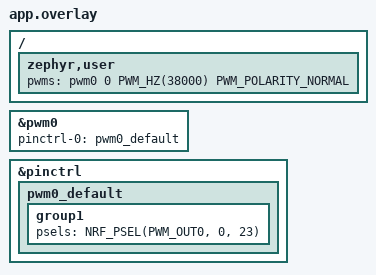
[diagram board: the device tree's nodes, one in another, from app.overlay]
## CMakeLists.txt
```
cmake_minimum_required(VERSION 3.20.0)
set(BOARD_ROOT ${CMAKE_CURRENT_SOURCE_DIR}/../.. CACHE PATH "")
find_package(Zephyr REQUIRED HINTS $ENV{ZEPHYR_BASE})
project(irtester)

target_sources(app PRIVATE
    src/main_rx_debug.c
    src/ir.c
)
```

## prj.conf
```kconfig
CONFIG_LOG=y
CONFIG_GPIO=y
CONFIG_PWM=y
```

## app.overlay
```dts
/ {
    zephyr,user {
        pwms = <&pwm0 0 PWM_HZ(38000) PWM_POLARITY_NORMAL>;
    };
};

&pwm0 {
    status = "okay";
    pinctrl-0 = <&pwm0_default>;
    pinctrl-names = "default";
};

&pinctrl {
    pwm0_default: pwm0_default {
        group1 {
            psels = <NRF_PSEL(PWM_OUT0, 0, 23)>;
        };
    };
};
```

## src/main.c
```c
#include <stdint.h>
#include <string.h>

#include <zephyr/kernel.h>
#include <zephyr/logging/log.h>
#include <zephyr/logging/log_core.h>

#include "ir.h"

LOG_MODULE_REGISTER(irtester, LOG_LEVEL_INF);

#define IR_MESSAGE "TH-1"
#define IR_MESSAGE_LEN (sizeof(IR_MESSAGE) - 1)

int main(void)
{
	int err;
	uint8_t decoded[IR_MESSAGE_LEN] = {0};
	int bytes_decoded;
	int edges_captured;

	LOG_INF("irtester starting");

	err = ir_tx_init();
	if (err) {
		return err;
	}

	err = ir_rx_init();
	if (err) {
		return err;
	}

	LOG_INF("Sending message \"%s\" over IR", IR_MESSAGE);

	ir_rx_capture_start();
	for (size_t i = 0; i < IR_MESSAGE_LEN; i++) {
		ir_send_byte((uint8_t)IR_MESSAGE[i]);
	}
	k_msleep(5);
	edges_captured = ir_rx_capture_stop();

	if (edges_captured == 0) {
		LOG_WRN("No response seen on the IR receiver at all");
		return 0;
	}

	LOG_INF("Response detected on IR receiver (%d edge(s))", edges_captured);

	bytes_decoded = ir_decode_capture(decoded, (int)IR_MESSAGE_LEN);
	if (bytes_decoded == (int)IR_MESSAGE_LEN &&
	    memcmp(decoded, IR_MESSAGE, IR_MESSAGE_LEN) == 0) {
		LOG_INF("Decoded message matches what was sent: \"%.*s\"",
			(int)IR_MESSAGE_LEN, decoded);
	} else {
		LOG_WRN("Only decoded %d of %zu byte(s):", bytes_decoded, IR_MESSAGE_LEN);
		for (int i = 0; i < bytes_decoded; i++) {
			char c = (decoded[i] >= 32 && decoded[i] < 127) ? (char)decoded[i] : '?';

			LOG_WRN("  byte %d: 0x%02x ('%c')", i, decoded[i], c);
		}
	}

	return 0;
}
```

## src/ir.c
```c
#include <errno.h>

#include <zephyr/kernel.h>
#include <zephyr/device.h>
#include <zephyr/devicetree.h>
#include <zephyr/drivers/gpio.h>
#include <zephyr/drivers/pwm.h>
#include <zephyr/sys/util.h>
#include <zephyr/sys/time_units.h>
#include <zephyr/logging/log.h>
#include <zephyr/logging/log_core.h>

#include "ir.h"

LOG_MODULE_REGISTER(ir, LOG_LEVEL_INF);

static const struct pwm_dt_spec pwm_ir = PWM_DT_SPEC_GET(DT_PATH(zephyr_user));
static const struct gpio_dt_spec ir_rx = GPIO_DT_SPEC_GET(DT_PATH(zephyr_user), ir_rx_gpios);

static struct gpio_callback ir_rx_cb_data;
static struct ir_edge capture_buf[IR_CAPTURE_MAX];
static volatile int capture_count;

static inline void ir_carrier_on(void)
{
	pwm_set_dt(&pwm_ir, pwm_ir.period, pwm_ir.period / 2);
}

static inline void ir_carrier_off(void)
{
	pwm_set_dt(&pwm_ir, pwm_ir.period, 0);
}

static void ir_mark(uint32_t us)
{
	ir_carrier_on();
	k_busy_wait(us);
	ir_carrier_off();
}

static void ir_space(uint32_t us)
{
	k_busy_wait(us);
}

static void ir_rx_isr(const struct device *port, struct gpio_callback *cb,
		       gpio_port_pins_t pins)
{
	ARG_UNUSED(port);
	ARG_UNUSED(cb);
	ARG_UNUSED(pins);

	if (capture_count >= IR_CAPTURE_MAX) {
		return;
	}

	capture_buf[capture_count].timestamp_cycles = k_cycle_get_32();
	capture_buf[capture_count].active = gpio_pin_get_dt(&ir_rx) == 1;
	capture_count++;
}

int ir_tx_init(void)
{
	if (!pwm_is_ready_dt(&pwm_ir)) {
		LOG_ERR("PWM device for IR TX is not ready");
		return -ENODEV;
	}

	return pwm_set_dt(&pwm_ir, pwm_ir.period, 0);
}

int ir_rx_init(void)
{
	int err;

	if (!gpio_is_ready_dt(&ir_rx)) {
		LOG_ERR("GPIO device for IR RX is not ready");
		return -ENODEV;
	}

	err = gpio_pin_configure_dt(&ir_rx, GPIO_INPUT);
	if (err) {
		LOG_ERR("Failed to configure IR RX pin as input (err: %d)", err);
		return err;
	}

	gpio_init_callback(&ir_rx_cb_data, ir_rx_isr, BIT(ir_rx.pin));

	err = gpio_add_callback_dt(&ir_rx, &ir_rx_cb_data);
	if (err) {
		LOG_ERR("Failed to add IR RX gpio callback (err: %d)", err);
		return err;
	}

	return 0;
}

void ir_send_byte(uint8_t byte)
{
	ir_mark(IR_HEADER_MARK_US);
	ir_space(IR_HEADER_SPACE_US);

	for (int i = 0; i < 8; i++) {
		ir_mark(IR_BIT_MARK_US);
		if (byte & BIT(i)) {
			ir_space(IR_ONE_SPACE_US);
		} else {
			ir_space(IR_ZERO_SPACE_US);
		}
	}

	ir_mark(IR_BIT_MARK_US);
	ir_carrier_off();
}

void ir_rx_capture_start(void)
{
	capture_count = 0;
	gpio_pin_interrupt_configure_dt(&ir_rx, GPIO_INT_EDGE_BOTH);
}

int ir_rx_capture_stop(void)
{
	gpio_pin_interrupt_configure_dt(&ir_rx, GPIO_INT_DISABLE);
	return capture_count;
}

static uint32_t edge_delta_us(int idx)
{
	uint32_t delta_cycles = capture_buf[idx + 1].timestamp_cycles -
				 capture_buf[idx].timestamp_cycles;

	return k_cyc_to_us_floor32(delta_cycles);
}

/* Finds a header mark at or after idx and returns the index of the start of
 * bit 0's mark (i.e. just past the header space), or -1 if no complete
 * header is found. Generous tolerance on the header mark's duration since
 * the two halves of this board are not aimed at each other and some
 * corruption is expected. */
static int find_header(int idx, int n)
{
	while (idx < n - 1) {
		if (capture_buf[idx].active &&
		    edge_delta_us(idx) > IR_HEADER_MARK_US / 2 &&
		    edge_delta_us(idx) < IR_HEADER_MARK_US * 2) {
			break;
		}
		idx++;
	}

	if (idx >= n - 1) {
		return -1;
	}

	idx++; /* the header space */

	if (idx >= n - 1 || capture_buf[idx].active) {
		return -1;
	}

	return idx + 1; /* start of bit 0's mark */
}

/* Decodes one 8 bit frame starting at idx (the start of bit 0's mark).
 * Returns the index just past the frame (its stop mark), and writes the
 * decoded byte to *out_byte. Stops early, returning a partial byte, if the
 * capture runs out of edges mid-frame. */
static int decode_frame(int idx, int n, uint8_t *out_byte)
{
	uint8_t byte = 0;

	for (int bit = 0; bit < 8 && idx < n - 1; bit++) {
		if (!capture_buf[idx].active) {
			break;
		}
		idx++; /* the bit's space */
		if (idx >= n - 1 || capture_buf[idx].active) {
			break;
		}

		if (edge_delta_us(idx) > (IR_ZERO_SPACE_US + IR_ONE_SPACE_US) / 2) {
			byte |= BIT(bit);
		}

		idx++;
	}

	*out_byte = byte;
	return idx;
}

int ir_decode_capture(uint8_t *out_bytes, int max_bytes)
{
	int n = capture_count;
	int idx = 0;
	int bytes_decoded = 0;

	LOG_INF("Captured %d edge(s)", n);

	for (int i = 0; i < n - 1; i++) {
		LOG_INF("  [%d] %s for %u us", i,
			capture_buf[i].active ? "mark" : "space", edge_delta_us(i));
	}

	if (n < 3) {
		LOG_WRN("Not enough edges captured to attempt a decode");
		return 0;
	}

	while (bytes_decoded < max_bytes) {
		int bit_start = find_header(idx, n);

		if (bit_start < 0) {
			break;
		}

		idx = decode_frame(bit_start, n, &out_bytes[bytes_decoded]);
		LOG_INF("Decoded byte %d: 0x%02x", bytes_decoded, out_bytes[bytes_decoded]);
		bytes_decoded++;
	}

	if (bytes_decoded < max_bytes) {
		LOG_WRN("Only decoded %d of %d expected byte(s)", bytes_decoded, max_bytes);
	}

	return bytes_decoded;
}
```

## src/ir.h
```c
#ifndef IR_H_
#define IR_H_

#include <stdint.h>

/* NEC-style timing unit, in microseconds. Standard for 38kHz AGC receivers
 * such as the VS1838B fitted on this board (S1). */
#define IR_UNIT_US        560
#define IR_HEADER_MARK_US  (16 * IR_UNIT_US)
#define IR_HEADER_SPACE_US (8  * IR_UNIT_US)
#define IR_BIT_MARK_US     (1  * IR_UNIT_US)
#define IR_ZERO_SPACE_US   (1  * IR_UNIT_US)
#define IR_ONE_SPACE_US    (3  * IR_UNIT_US)

/* 4 frames (header + 8 bit mark/space pairs + stop mark = 20 timestamps
 * each), plus headroom. */
#define IR_CAPTURE_MAX 96

struct ir_edge {
	uint32_t timestamp_cycles;
	uint8_t active; /* 1 = mark (receiver output active), 0 = space */
};

int ir_tx_init(void);
int ir_rx_init(void);

/* Encodes and sends one byte, LSB first, as a NEC-style header + 8 bit
 * mark/space pairs + stop mark. Blocks for the duration of the transmission. */
void ir_send_byte(uint8_t byte);

/* Clears the capture buffer and (re)arms the RX interrupt. */
void ir_rx_capture_start(void);

/* Disarms the RX interrupt and returns how many edges were captured. */
int ir_rx_capture_stop(void);

/* Logs the raw captured edges and attempts a best-effort decode of up to
 * max_bytes NEC-style frames, stopping early if a header can't be found or
 * a frame runs out of edges. Returns the number of bytes fully decoded
 * (0 to max_bytes); out_bytes holds that many decoded bytes. */
int ir_decode_capture(uint8_t *out_bytes, int max_bytes);

#endif /* IR_H_ */
```

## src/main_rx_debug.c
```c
#include <stdint.h>

#include <zephyr/kernel.h>
#include <zephyr/logging/log.h>
#include <zephyr/logging/log_core.h>

#include "ir.h"

LOG_MODULE_REGISTER(irtester, LOG_LEVEL_INF);

int main(void)
{
	int err;
	uint8_t unused[1];

	LOG_INF("irtester (rx debug) starting");

	err = ir_rx_init();
	if (err) {
		return err;
	}

	LOG_INF("Receiver armed. Point a remote at it.");

	while (1) {
		ir_rx_capture_start();
		k_msleep(200);
		int edges = ir_rx_capture_stop();

		if (edges > 0) {
			/* max_bytes=0: dumps the raw captured edges without
			 * attempting our own NEC frame decode, since a real
			 * remote won't necessarily use our timing. */
			ir_decode_capture(unused, 0);
		}
	}
}
```
